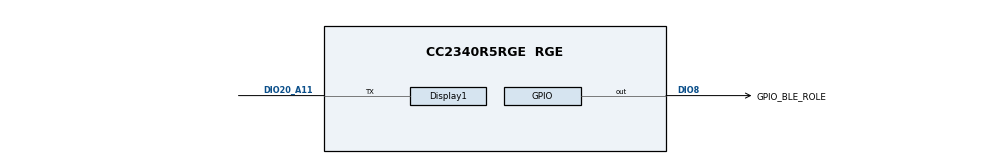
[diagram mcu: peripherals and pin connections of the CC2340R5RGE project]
/**
 * @cliArgs --device "CC2340R5RGE" --package "RGE" --part "Default" --rtos "freertos" --product "simplelink_lowpower_f3_sdk@8.10.01.02"
 * @versions {"tool":"1.20.0+3587"}
 */

/**
 * Import the modules used in this configuration.
 */
const FreeRTOS    = scripting.addModule("/freertos/FreeRTOS");
const ble         = scripting.addModule("/ti/ble5stack/ble");
const CCFG        = scripting.addModule("/ti/devices/CCFG");
const rfdesign    = scripting.addModule("/ti/devices/radioconfig/rfdesign");
const Display     = scripting.addModule("/ti/display/Display");
const Display1    = Display.addInstance();
const AESCCM      = scripting.addModule("/ti/drivers/AESCCM");
const AESCCM1     = AESCCM.addInstance();
const AESCTRDRBG  = scripting.addModule("/ti/drivers/AESCTRDRBG");
const AESCTRDRBG1 = AESCTRDRBG.addInstance();
const AESECB      = scripting.addModule("/ti/drivers/AESECB");
const AESECB1     = AESECB.addInstance();
const ECDH        = scripting.addModule("/ti/drivers/ECDH");
const ECDH1       = ECDH.addInstance();
const GPIO        = scripting.addModule("/ti/drivers/GPIO");
const GPIO3       = GPIO.addInstance();
const LGPTimer    = scripting.addModule("/ti/drivers/LGPTimer", {}, false);
const LGPTimer1   = LGPTimer.addInstance();
const NVS         = scripting.addModule("/ti/drivers/NVS");
const NVS1        = NVS.addInstance();
const NVS2        = NVS.addInstance();
const Power       = scripting.addModule("/ti/drivers/Power");
const RCL         = scripting.addModule("/ti/drivers/RCL");
const RNG         = scripting.addModule("/ti/drivers/RNG");
const RNG1        = RNG.addInstance();
const Button      = scripting.addModule("/ti/drivers/apps/Button", {}, false);
const Button1     = Button.addInstance();
const Button2     = Button.addInstance();
const Settings    = scripting.addModule("/ti/posix/freertos/Settings");

/**
 * Write custom configuration values to the imported modules.
 */
FreeRTOS.timerStackSize       = 0x00000190;
FreeRTOS.idleStackSize        = 0x00000550;
FreeRTOS.posixThreadStackSize = 0x00000550;
FreeRTOS.heapSize             = 0x00005200;

ble.basicBLE                           = true;
ble.disDevBySerUuid                    = true;
ble.numOfAdvSets                       = 1;
ble.numOfDefAdvSets                    = 1;
ble.addressMode                        = "ADDRMODE_PUBLIC";
ble.deviceRole                         = "PERIPHERAL_CFG+CENTRAL_CFG";
ble.maxNumPrepareWrites                = 10;
ble.defaultTxPowerValue                = "8";
ble.maxPDUSize                         = 255;
ble.disableDisplayModule               = true;
ble.connIntMin                         = 7.5;
ble.connIntMax                         = 7.5;
ble.maxConnNum                         = 4;
ble.deviceName                         = "";
ble.centraSupTimeout                   = 100;
ble.bondPairing                        = "GAPBOND_PAIRING_MODE_INITIATE";
ble.bondFailAction                     = "GAPBOND_FAIL_TERMINATE_LINK";
ble.maxBonds                           = 3;
ble.authenPairingOnly                  = true;
ble.radioConfig.codeExportConfig.$name = "ti_devices_radioconfig_code_export_param0";
ble.connUpdateParamsPeripheral.$name   = "ti_ble5stack_general_ble_conn_update_params0";
ble.connUpdateParamsCentral.$name      = "ti_ble5stack_general_ble_conn_update_params1";
ble.advSet1.$name                      = "ti_ble5stack_broadcaster_advertisement_set0";
ble.advSet1.advParam1.$name            = "ti_ble5stack_broadcaster_advertisement_params0";
ble.advSet1.advData1.$name             = "ti_ble5stack_broadcaster_advertisement_data0";
ble.advSet1.scanRes1.$name             = "ti_ble5stack_broadcaster_advertisement_data1";

CCFG.ccfgTemplate.$name = "ti_devices_CCFG_CCFGCC23X0Template0";

Display1.$name                    = "CONFIG_Display_0";
Display1.enableANSI               = true;
Display1.uartBufferSize           = 128;
Display1.uart.$name               = "CONFIG_DISPLAY_UART";
Display1.uart.rxRingBufferSize    = 64;
Display1.uart.txRingBufferSize    = 64;
Display1.uart.uart.txPin.$assign  = "DIO20_A11";
Display1.uart.txPinInstance.$name = "CONFIG_PIN_UART_TX";
Display1.uart.rxPinInstance.$name = "CONFIG_PIN_UART_RX";

AESCCM1.$name = "CONFIG_AESCCM0";

AESCTRDRBG1.$name = "CONFIG_AESCTRDRBG_0";

AESECB1.$name = "CONFIG_AESECB0";

ECDH1.$name = "CONFIG_ECDH0";

GPIO3.$name            = "GPIO_BLE_ROLE";
GPIO3.pull             = "Pull Down";
GPIO3.interruptTrigger = "Rising Edge";
GPIO3.gpioPin.$assign  = "DIO8";

LGPTimer1.$name             = "CONFIG_LGPTIMER_3";
LGPTimer1.interruptPriority = "2";
LGPTimer1.timer.$assign     = "LGPT3";

NVS1.$name                    = "CONFIG_NVSINTERNAL";
NVS1.internalFlash.$name      = "ti_drivers_nvs_NVSLPF30";
NVS1.internalFlash.regionBase = 0x7C000;
NVS1.internalFlash.regionSize = 0x4000;

NVS2.$name                    = "CONFIG_NVSINTERNAL1";
NVS2.internalFlash.$name      = "ti_drivers_nvs_NVSLPF31";
NVS2.internalFlash.regionBase = 0x32000;
NVS2.internalFlash.regionSize = 0x4A000;
NVS2.internalFlash.regionType = "Pointer";

RNG1.$name = "CONFIG_RNG_0";

Button1.$name = "CONFIG_BUTTON_0";

Button2.$name = "CONFIG_BUTTON_1";

/**
 * Pinmux solution for unlocked pins/peripherals. This ensures that minor changes to the automatic solver in a future
 * version of the tool will not impact the pinmux you originally saw.  These lines can be completely deleted in order to
 * re-solve from scratch.
 */
Display1.uart.uart.$suggestSolution              = "UART0";
Display1.uart.uart.dmaTxChannel.$suggestSolution = "DMA_CH1";
Display1.uart.uart.dmaRxChannel.$suggestSolution = "DMA_CH0";
Display1.uart.uart.rxPin.$suggestSolution        = "DIO12";
Button1.button.$suggestSolution                  = "DIO11";
Button2.button.$suggestSolution                  = "DIO11";
